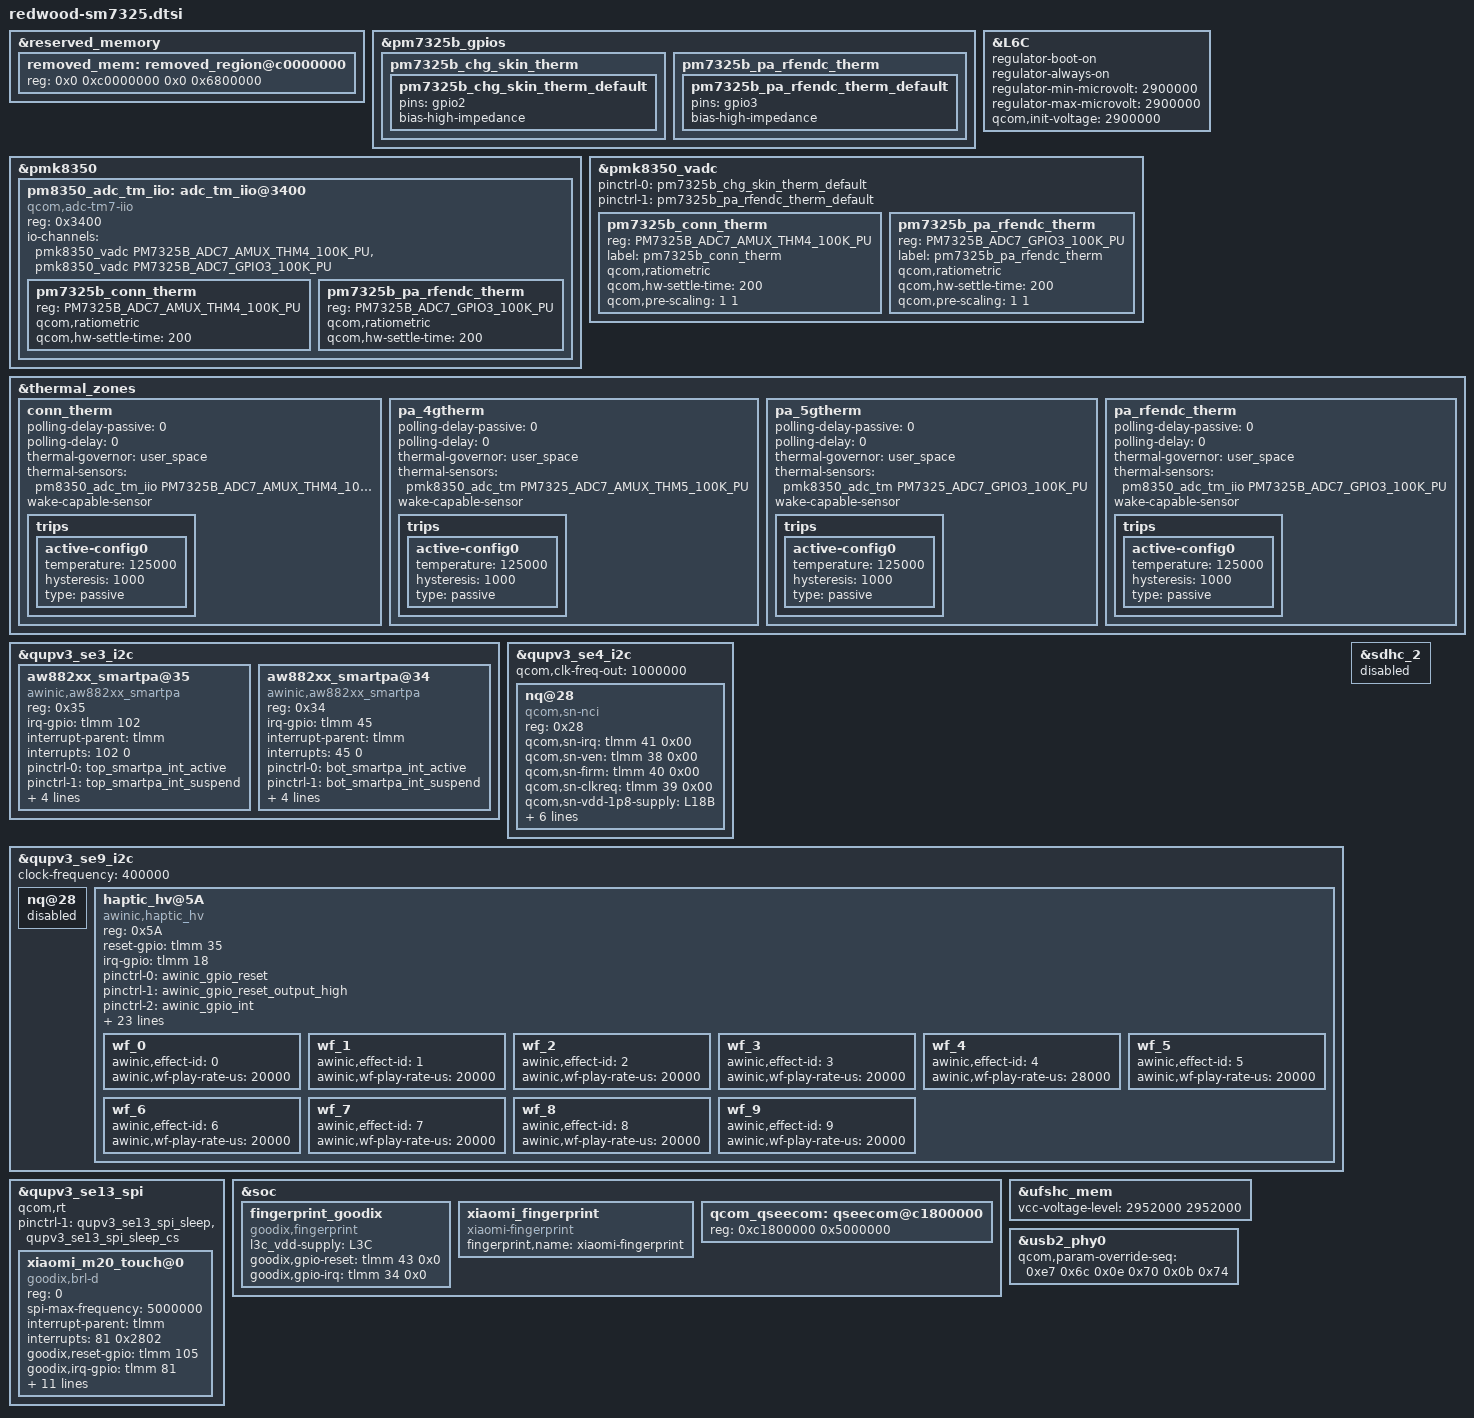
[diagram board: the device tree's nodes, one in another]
// This file is for attribution of redwood and Xiaomi platform only

#include "redwood-pinctrl.dtsi"
#include "xiaomi-sm7325-common.dtsi"
#include "camera/redwood-sm7325-camera-sensor.dtsi"
#include "display/redwood-sm7325-sde-display.dtsi"
#include "redwood-audio-overlay.dtsi"

&reserved_memory {
	removed_mem: removed_region@c0000000 {
		reg = <0x0 0xc0000000 0x0 0x6800000>;
	};
};

/*
 * PM7325B device specific diff for Xiaomi Redwood platform
 */
&pm7325b_gpios {
	// Disable PM7325B GPIO_2_3 to fix inaccurate temp value

	pm7325b_chg_skin_therm {
		pm7325b_chg_skin_therm_default: pm7325b_chg_skin_therm_default {
			pins = "gpio2";
			bias-high-impedance;
		};
	};

	pm7325b_pa_rfendc_therm {
		pm7325b_pa_rfendc_therm_default: pm7325b_pa_rfendc_therm_default {
			pins = "gpio3";
			bias-high-impedance;
		};
	};
};

/*
 * PM8350C devices specific diff for Xiaomi Redwood platform
 */
&L6C {
	regulator-boot-on; /* M20 for RF ANT Detect MXD8625C Switch IC */
	regulator-always-on;
	regulator-min-microvolt = <2900000>;
	regulator-max-microvolt = <2900000>;
	qcom,init-voltage = <2900000>;
};

/*
 * PMK8350 device specific diff for Xiaomi Redwood platform
 */
&pmk8350 {
	pm8350_adc_tm_iio: adc_tm_iio@3400 {
		compatible = "qcom,adc-tm7-iio";
		reg = <0x3400>;
		#thermal-sensor-cells = <1>;
		#address-cells = <1>;
		#size-cells = <0>;

		io-channels = <&pmk8350_vadc PM7325B_ADC7_AMUX_THM4_100K_PU>,
					  <&pmk8350_vadc PM7325B_ADC7_GPIO3_100K_PU>;

		pm7325b_conn_therm {
			reg = <PM7325B_ADC7_AMUX_THM4_100K_PU>;
			qcom,ratiometric;
			qcom,hw-settle-time = <200>;
		};

		pm7325b_pa_rfendc_therm {
			reg = <PM7325B_ADC7_GPIO3_100K_PU>;
			qcom,ratiometric;
			qcom,hw-settle-time = <200>;
		};
	};
};

&pmk8350_vadc {
	// Disable PM7325B GPIO_2_3 to fix inaccurate temp value
	pinctrl-names = "default";
	pinctrl-0 = <&pm7325b_chg_skin_therm_default>;
	pinctrl-1 = <&pm7325b_pa_rfendc_therm_default>;

	pm7325b_conn_therm {
		reg = <PM7325B_ADC7_AMUX_THM4_100K_PU>;
		label = "pm7325b_conn_therm";
		qcom,ratiometric;
		qcom,hw-settle-time = <200>;
		qcom,pre-scaling = <1 1>;
	};

	pm7325b_pa_rfendc_therm {
		reg = <PM7325B_ADC7_GPIO3_100K_PU>;
		label = "pm7325b_pa_rfendc_therm";
		qcom,ratiometric;
		qcom,hw-settle-time = <200>;
		qcom,pre-scaling = <1 1>;
	};
};

&thermal_zones {
	conn_therm {
		polling-delay-passive = <0>;
		polling-delay = <0>;
		thermal-governor = "user_space";
		thermal-sensors = <&pm8350_adc_tm_iio PM7325B_ADC7_AMUX_THM4_100K_PU>;
		wake-capable-sensor;

		trips {
			active-config0 {
				temperature = <125000>;
				hysteresis = <1000>;
				type = "passive";
			};
		};
	};

	pa_4gtherm {
		polling-delay-passive = <0>;
		polling-delay = <0>;
		thermal-governor = "user_space";
		thermal-sensors = <&pmk8350_adc_tm PM7325_ADC7_AMUX_THM5_100K_PU>;
		wake-capable-sensor;

		trips {
			active-config0 {
				temperature = <125000>;
				hysteresis = <1000>;
				type = "passive";
			};
		};
	};

	pa_5gtherm {
		polling-delay-passive = <0>;
		polling-delay = <0>;
		thermal-governor = "user_space";
		thermal-sensors = <&pmk8350_adc_tm PM7325_ADC7_GPIO3_100K_PU>;
		wake-capable-sensor;

		trips {
			active-config0 {
				temperature = <125000>;
				hysteresis = <1000>;
				type = "passive";
			};
		};
	};

	pa_rfendc_therm {
		polling-delay-passive = <0>;
		polling-delay = <0>;
		thermal-governor = "user_space";
		thermal-sensors = <&pm8350_adc_tm_iio PM7325B_ADC7_GPIO3_100K_PU>;
		wake-capable-sensor;

		trips {
			active-config0 {
				temperature = <125000>;
				hysteresis = <1000>;
				type = "passive";
			};
		};
	};
};

// Awinic AW88261 Smart Amp
&qupv3_se3_i2c {
	status = "ok";

	/* TOP Smart PA */
	aw882xx_smartpa@35 {
		compatible = "awinic,aw882xx_smartpa";
		reg = <0x35>;
		irq-gpio = <&tlmm 102 0>;
		interrupt-parent = <&tlmm>;
		interrupts = <102 0>;
		interrupt-names = "smartpa_irq";
		pinctrl-names = "default", "sleep";
		pinctrl-0 = <&top_smartpa_int_active>;
		pinctrl-1 = <&top_smartpa_int_suspend>;
		aw-re-min = <4000>;
		aw-re-max = <30000>;
		aw-cali-mode = "aw_class";
		sound-channel = <0>;
		status = "ok";
	};

	/* BOT Smart PA */
	aw882xx_smartpa@34 {
		compatible = "awinic,aw882xx_smartpa";
		reg = <0x34>;
		irq-gpio = <&tlmm 45 0>;
		interrupt-parent = <&tlmm>;
		interrupts = <45 0>;
		interrupt-names = "smartpa_irq";
		pinctrl-names = "default", "sleep";
		pinctrl-0 = <&bot_smartpa_int_active>;
		pinctrl-1 = <&bot_smartpa_int_suspend>;
		aw-re-min = <4000>;
		aw-re-max = <30000>;
		aw-cali-mode = "aw_class";
		sound-channel = <1>;
		status = "ok";
	};
};

&qupv3_se4_i2c {
	status = "ok";
	qcom,clk-freq-out = <1000000>;
	#address-cells = <1>;
	#size-cells = <0>;
	nq@28 {
		compatible = "qcom,sn-nci";
		reg = <0x28>;
		qcom,sn-irq = <&tlmm 41 0x00>;
		qcom,sn-ven = <&tlmm 38 0x00>;
		qcom,sn-firm = <&tlmm 40 0x00>;
		qcom,sn-clkreq = <&tlmm 39 0x00>;
		qcom,sn-vdd-1p8-supply = <&L18B>;
		qcom,sn-vdd-1p8-voltage = <1800000 1800000>;
		qcom,sn-vdd-1p8-current = <157000>;
		interrupt-parent = <&tlmm>;
		interrupts = <41 0>;
		interrupt-names = "nfc_irq";
		pinctrl-names = "nfc_active", "nfc_suspend";
		pinctrl-0 = <&nfc_int_active &nfc_enable_active>;
		pinctrl-1 = <&nfc_int_suspend &nfc_enable_suspend>;
	};
};

&qupv3_se9_i2c {
	#address-cells = <1>;
	#size-cells = <0>;
	clock-frequency = <400000>;
	status = "ok";

	nq@28 {
		status = "disabled";
	};

	haptic_hv@5A {
		status = "ok";
		compatible = "awinic,haptic_hv";
		reg = <0x5A>;

		reset-gpio = <&tlmm 35 0x00>;
		irq-gpio = <&tlmm 18 0x00>;

		pinctrl-names = "awinic_reset_reset",
						"awinic_reset_active",
						"awinic_interrupt_active";

		pinctrl-0 = <&awinic_gpio_reset>;
		pinctrl-1 = <&awinic_gpio_reset_output_high>;
		pinctrl-2 = <&awinic_gpio_int>;

		mode = <1>;
		f0_pre = <1700>;

		/*************aw8692x***************/
		aw8692x_f0_cali_percent = /bits/ 8 < 7 >;
		aw8692x_cont_drv1_lvl =  /bits/ 8 <0x4F>;
		aw8692x_cont_drv2_lvl = /bits/ 8 <0x28>;
		aw8692x_cont_drv1_time = /bits/ 8 <0x04>;
		aw8692x_cont_drv2_time = /bits/ 8 <0x06>;
		aw8692x_cont_wait_num = /bits/ 8 < 0x06 >;
		aw8692x_gain_bypass = /bits/ 8 <0x01>;
		aw8692x_cont_track_margin = /bits/ 8 <0x0C>;
		aw8692x_brk_bst_md = /bits/ 8 <0>;
		aw8692x_cont_tset = /bits/ 8 < 0x06 >;
		aw8692x_cont_bemf_set = /bits/ 8 < 0x02 >;
		aw86927_vib_cont_bst_brk_gain = /bits/ 8 <0x05>;
		aw8692x_cont_brk_gain = /bits/ 8 <0x08>;
		aw8692x_cont_brk_time = /bits/ 8 <0x08>;
		aw8692x_duration_time = /bits/ 8 <20 30 60>;
		aw8692x_d2s_gain = /bits/ 8 <0x04>;
		aw8692x_trig_config = /bits/ 8 <0 0 0 1 0 2 0 0
										0 0 0 1 0 2 0 0
										0 0 0 1 0 2 0 0>;
		aw8692x_bst_vol_default = < 8000>;
		aw8692x_is_enabled_track_en;
		awinic,support_predefined_pattern;

		/*CLICK*/
		wf_0 {
			awinic,effect-id = <0>;
			awinic,wf-play-rate-us = <20000>;
		};

		/*DOUBLE CLICK*/
		wf_1 {
			awinic,effect-id = <1>;
			awinic,wf-play-rate-us = <20000>;
		};

		/*TICK*/
		wf_2 {
			awinic,effect-id = <2>;
			awinic,wf-play-rate-us = <20000>;
		};

		/*THUD*/
		wf_3 {
			awinic,effect-id = <3>;
			awinic,wf-play-rate-us = <20000>;
		};

		/*POP*/
		wf_4 {
			awinic,effect-id = <4>;
			awinic,wf-play-rate-us = <28000>;
		};

		/*HEAVY CLICK*/
		wf_5 {
			awinic,effect-id = <5>;
			awinic,wf-play-rate-us = <20000>;
		};

		/*ID 6*/
		wf_6 {
			awinic,effect-id = <6>;
			awinic,wf-play-rate-us = <20000>;
		};

		/*ID 7*/
		wf_7 {
			awinic,effect-id = <7>;
			awinic,wf-play-rate-us = <20000>;
		};

		/*ID 8*/
		wf_8 {
			awinic,effect-id = <8>;
			awinic,wf-play-rate-us = <20000>;
		};

		/*ID 9*/
		wf_9 {
			awinic,effect-id = <9>;
			awinic,wf-play-rate-us = <20000>;
		};
	};
};

&qupv3_se13_spi {
	status = "ok";
	qcom,rt;
	pinctrl-1 = <&qupv3_se13_spi_sleep &qupv3_se13_spi_sleep_cs>;

	xiaomi_m20_touch@0 {
		compatible = "goodix,brl-d";
		reg = <0>;
		spi-max-frequency = <5000000>;
		interrupt-parent = <&tlmm>;
		interrupts = <81 0x2802>;

		goodix,reset-gpio = <&tlmm 105 0x00>;
		goodix,irq-gpio = <&tlmm 81 0x2802>;
		goodix,irq-flags = <2>;
		goodix,panel-max-x = <10800>;
		goodix,panel-max-y = <24000>;
		goodix,panel-max-w = <255>;
		goodix,panel-max-p = <4096>;
		goodix,firmware-name = "goodix_firmware_m20.bin";
		goodix,config-name = "goodix_cfg_group_m20.bin";
		goodix,sleep-enable;

		goodix,iovdd-name = "vdd";
		goodix,avdd-gpio = <&tlmm 107 0x00>;

		vdd-supply = <&L2C>;
	};
};

&soc {
	fingerprint_goodix {
		compatible = "goodix,fingerprint";
		l3c_vdd-supply = <&L3C>;
		goodix,gpio-reset = <&tlmm 43 0x0>;
		goodix,gpio-irq = <&tlmm 34 0x0>;
		status = "ok";
	};

	xiaomi_fingerprint {
		compatible = "xiaomi-fingerprint";
		fingerprint,name = "xiaomi-fingerprint";
		status = "ok";
	};

	qcom_qseecom: qseecom@c1800000 {
		reg = <0xc1800000 0x5000000>;
		reg-names = "secapp-region";
	};
};

&sdhc_2 {
	status = "disabled";
};

&ufshc_mem {
	vcc-voltage-level = <2952000 2952000>;
};

&usb2_phy0 {
	qcom,param-override-seq =
		<0xe7 0x6c  	/* override_x0 */
		 0x0e 0x70  	/* override_x1 */
		 0x0b 0x74>;	/* override x2 */
};
